# PIC32CX1025SG41128 register map
Vendor: Microchip Technology; Series: PIC32CXSG41; File version: 0
CPU: CM4 r0p1, selectable endian, MPU, FPU, 3 interrupt priority bits, 137 interrupts
Registers are 32-bit, read-write, reset 0x0 unless marked. A register's access mark holds for its fields unless they carry their own. Offsets are from the block's base; [hi:lo] are bit positions; {n}, {i} and the like mark numbered series; 'fields as' and 'values as' point back to an identical list.

## TRNG — True Random Generator
Base 0x42002800; register names take the prefix TRNG_
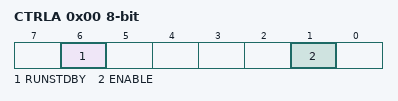
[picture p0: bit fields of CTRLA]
0x00 CTRLA 8-bit — Control A
  [6] RUNSTDBY — Run in Standby
  [1] ENABLE
0x04 EVCTRL 8-bit — Event Control
  [0] DATARDYEO — Data Ready Event Output
0x08 INTENCLR 8-bit — Interrupt Enable Clear
  [0] DATARDY — Data Ready Interrupt Enable
0x09 INTENSET 8-bit — Interrupt Enable Set
  [0] DATARDY — Data Ready Interrupt Enable
0x0A INTFLAG 8-bit — Interrupt Flag Status and Clear
  [0] DATARDY — Data Ready Interrupt Flag
0x20 DATA ro — Output Data

## WDT — Watchdog Timer
Base 0x40002000; register names take the prefix WDT_
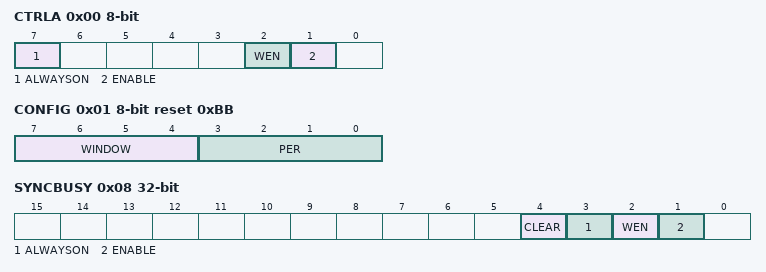
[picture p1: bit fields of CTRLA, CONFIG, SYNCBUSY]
0x00 CTRLA 8-bit — Control
  [7] ALWAYSON
  [2] WEN — Watchdog Timer Window Mode Enable
  [1] ENABLE
0x01 CONFIG 8-bit reset 0xBB — Configuration
  [7:4] WINDOW — Window Mode Time-Out Period
    0=CYC8 (8 clock cycles); 1=CYC16 (16 clock cycles); 2=CYC32 (32 clock cycles); 3=CYC64 (64 clock cycles); 4=CYC128 (128 clock cycles); 5=CYC256 (256 clock cycles); 6=CYC512 (512 clock cycles); 7=CYC1024 (1024 clock cycles); 8=CYC2048 (2048 clock cycles); 9=CYC4096 (4096 clock cycles); 10=CYC8192 (8192 clock cycles); 11=CYC16384 (16384 clock cycles)
  [3:0] PER — Time-Out Period
    values as WINDOW
0x02 EWCTRL 8-bit reset 0xB — Early Warning Interrupt Control
  [3:0] EWOFFSET — Early Warning Interrupt Time Offset
    0=CYC8 (8 clock cycles); 1=CYC16 (16 clock cycles); 2=CYC32 (32 clock cycles); 3=CYC64 (64 clock cycles); 4=CYC128 (128 clock cycles); 5=CYC256 (256 clock cycles); 6=CYC512 (512 clock cycles); 7=CYC1024 (1024 clock cycles); 8=CYC2048 (2048 clock cycles); 9=CYC4096 (4096 clock cycles); 10=CYC8192 (8192 clock cycles)
0x04 INTENCLR 8-bit — Interrupt Enable Clear
  [0] EW — Early Warning Interrupt Enable
0x05 INTENSET 8-bit — Interrupt Enable Set
  [0] EW — Early Warning Interrupt Enable
0x06 INTFLAG 8-bit — Interrupt Flag Status and Clear
  [0] EW — Early Warning
0x08 SYNCBUSY ro — Synchronization Busy
  [4] CLEAR — Clear Synchronization Busy
  [3] ALWAYSON — Always-On Synchronization Busy
  [2] WEN — Window Enable Synchronization Busy
  [1] ENABLE — Enable Synchronization Busy
0x0C CLEAR 8-bit wo
  [7:0] CLEAR — Watchdog Clear
    165=KEY (Clear Key)

## CoreDebug
Base 0xE000EDF0; register names take the prefix CoreDebug_
0x00 DHCSR — Debug Halting Control and Status Register
  [25] S_RESET_ST ro, [24] S_RETIRE_ST ro, [19] S_LOCKUP ro, [18] S_SLEEP ro, [17] S_HALT ro, [16] S_REGRDY ro, [31:16] DBGKEY wo, [5] C_SNAPSTALL, [3] C_MASKINTS, [2] C_STEP, [1] C_HALT, [0] C_DEBUGEN
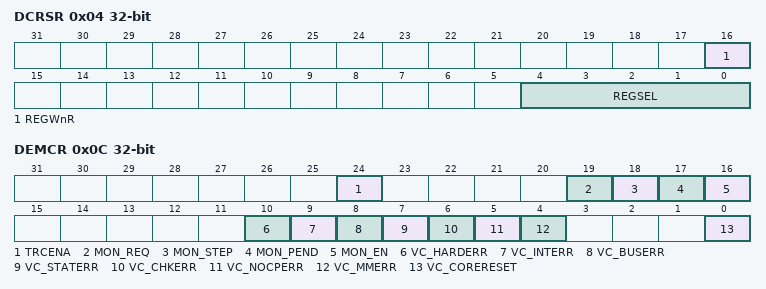
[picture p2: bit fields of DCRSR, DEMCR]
0x04 DCRSR wo — Debug Core Register Selector Register
  [16] REGWnR, [4:0] REGSEL
0x08 DCRDR — Debug Core Register Data Register
0x0C DEMCR — Debug Exception and Monitor Control Register
  [24] TRCENA, [19] MON_REQ, [18] MON_STEP, [17] MON_PEND, [16] MON_EN, [10] VC_HARDERR, [9] VC_INTERR, [8] VC_BUSERR, [7] VC_STATERR, [6] VC_CHKERR, [5] VC_NOCPERR, [4] VC_MMERR, [0] VC_CORERESET

## DWT — Data Watchpoint and Trace Register
Base 0xE0001000; register names take the prefix DWT_
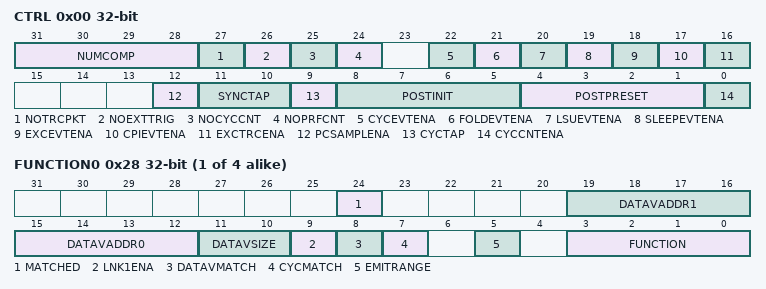
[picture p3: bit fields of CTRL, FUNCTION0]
0x00 CTRL — Control Register
  [31:28] NUMCOMP, [27] NOTRCPKT, [26] NOEXTTRIG, [25] NOCYCCNT, [24] NOPRFCNT, [22] CYCEVTENA, [21] FOLDEVTENA, [20] LSUEVTENA, [19] SLEEPEVTENA, [18] EXCEVTENA, [17] CPIEVTENA, [16] EXCTRCENA, [12] PCSAMPLENA, [11:10] SYNCTAP, [9] CYCTAP, [8:5] POSTINIT, [4:1] POSTPRESET, [0] CYCCNTENA
0x04 CYCCNT — Cycle Count Register
0x08 CPICNT — CPI Count Register
  [7:0] CPICNT
0x0C EXCCNT — Exception Overhead Count Register
  [7:0] EXCCNT
0x10 SLEEPCNT — Sleep Count Register
  [7:0] SLEEPCNT
0x14 LSUCNT — LSU Count Register
  [7:0] LSUCNT
0x18 FOLDCNT — Folded-instruction Count Register
  [7:0] FOLDCNT
0x1C PCSR ro — Program Counter Sample Register
{0x20+0x10*i} COMP{i} (i=0..3) — Comparator Register {i}
{0x24+0x10*i} MASK{i} (i=0..3) — Mask Register {i}
  [4:0] MASK
{0x28+0x10*i} FUNCTION{i} (i=0..3) — Function Register {i}
  [24] MATCHED, [19:16] DATAVADDR1, [15:12] DATAVADDR0, [11:10] DATAVSIZE, [9] LNK1ENA, [8] DATAVMATCH, [7] CYCMATCH, [5] EMITRANGE, [3:0] FUNCTION

## Notices in the file
Copyright (c) 2022 Microchip Technology Inc.
SPDX-License-Identifier: Apache-2.0
Licensed under the Apache License, Version 2.0 (the "License");
you may not use this file except in compliance with the License.
You may obtain a copy of the License at
http://www.apache.org/licenses/LICENSE-2.0
Unless required by applicable law or agreed to in writing, software
distributed under the License is distributed on an "AS IS" BASIS,
WITHOUT WARRANTIES OR CONDITIONS OF ANY KIND, either express or implied.
See the License for the specific language governing permissions and
limitations under the License.
